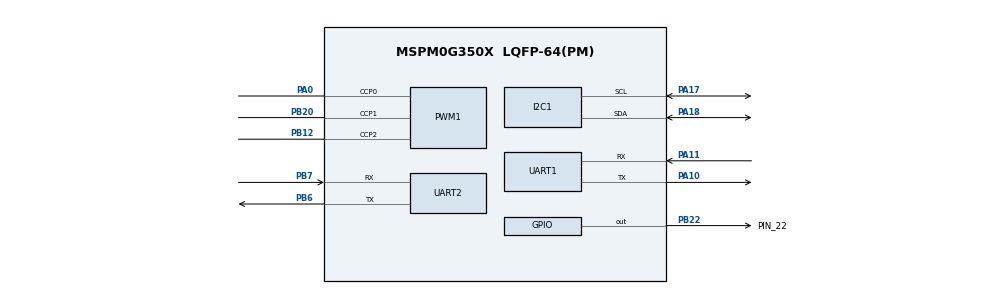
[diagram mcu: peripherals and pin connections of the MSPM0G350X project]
/**
 * @cliArgs --device "MSPM0G350X" --part "Default" --package "LQFP-64(PM)" --product "mspm0_sdk@2.10.00.04"
 * @versions {"tool":"1.26.2+4477"}
 */

/**
 * Import the modules used in this configuration.
 */
const GPIO    = scripting.addModule("/ti/driverlib/GPIO", {}, false);
const GPIO1   = GPIO.addInstance();
const GPIO2   = GPIO.addInstance();
const I2C     = scripting.addModule("/ti/driverlib/I2C", {}, false);
const I2C1    = I2C.addInstance();
const PWM     = scripting.addModule("/ti/driverlib/PWM", {}, false);
const PWM1    = PWM.addInstance();
const PWM2    = PWM.addInstance();
const SYSCTL  = scripting.addModule("/ti/driverlib/SYSCTL");
const SYSTICK = scripting.addModule("/ti/driverlib/SYSTICK");
const UART    = scripting.addModule("/ti/driverlib/UART", {}, false);
const UART1   = UART.addInstance();
const UART2   = UART.addInstance();

/**
 * Write custom configuration values to the imported modules.
 */
const divider9       = system.clockTree["UDIV"];
divider9.divideValue = 2;

const multiplier2         = system.clockTree["PLL_QDIV"];
multiplier2.multiplyValue = 4;

const mux4       = system.clockTree["EXHFMUX"];
mux4.inputSelect = "EXHFMUX_XTAL";

const mux8       = system.clockTree["HSCLKMUX"];
mux8.inputSelect = "HSCLKMUX_SYSPLL0";

const mux12       = system.clockTree["SYSPLLMUX"];
mux12.inputSelect = "zSYSPLLMUX_HFCLK";

const pinFunction4     = system.clockTree["HFXT"];
pinFunction4.enable    = true;
pinFunction4.inputFreq = 40;

GPIO1.$name                         = "use_led";
GPIO1.port                          = "PORTB";
GPIO1.associatedPins[0].$name       = "PIN_22";
GPIO1.associatedPins[0].pin.$assign = "PB22";

const Board = scripting.addModule("/ti/driverlib/Board", {}, false);

GPIO2.$name                          = "MG310";
GPIO2.associatedPins.create(4);
GPIO2.associatedPins[0].assignedPort = "PORTA";
GPIO2.associatedPins[0].$name        = "AIN1";
GPIO2.associatedPins[1].assignedPort = "PORTA";
GPIO2.associatedPins[1].$name        = "AIN2";
GPIO2.associatedPins[2].assignedPort = "PORTB";
GPIO2.associatedPins[2].$name        = "BIN1";
GPIO2.associatedPins[3].assignedPort = "PORTB";
GPIO2.associatedPins[3].$name        = "BIN2";

I2C1.$name                             = "as5600";
I2C1.basicEnableController             = true;
I2C1.basicControllerStandardBusSpeed   = "Fast";
I2C1.peripheral.$assign                = "I2C1";
I2C1.peripheral.sdaPin.$assign         = "PA18";
I2C1.peripheral.sclPin.$assign         = "PA17";
I2C1.sdaPinConfig.hideOutputInversion  = scripting.forceWrite(false);
I2C1.sdaPinConfig.onlyInternalResistor = scripting.forceWrite(false);
I2C1.sdaPinConfig.passedPeripheralType = scripting.forceWrite("Digital");
I2C1.sdaPinConfig.$name                = "ti_driverlib_gpio_GPIOPinGeneric5";
I2C1.sclPinConfig.hideOutputInversion  = scripting.forceWrite(false);
I2C1.sclPinConfig.onlyInternalResistor = scripting.forceWrite(false);
I2C1.sclPinConfig.passedPeripheralType = scripting.forceWrite("Digital");
I2C1.sclPinConfig.$name                = "ti_driverlib_gpio_GPIOPinGeneric6";

PWM1.$name                              = "BLDC";
PWM1.ccIndex                            = [0,1,2];
PWM1.timerCount                         = 1066;
PWM1.PWM_CHANNEL_0.$name                = "ti_driverlib_pwm_PWMTimerCC0";
PWM1.PWM_CHANNEL_1.$name                = "ti_driverlib_pwm_PWMTimerCC1";
PWM1.ccp0PinConfig.direction            = scripting.forceWrite("OUTPUT");
PWM1.ccp0PinConfig.hideOutputInversion  = scripting.forceWrite(false);
PWM1.ccp0PinConfig.onlyInternalResistor = scripting.forceWrite(false);
PWM1.ccp0PinConfig.passedPeripheralType = scripting.forceWrite("Digital");
PWM1.ccp0PinConfig.$name                = "ti_driverlib_gpio_GPIOPinGeneric0";
PWM1.ccp1PinConfig.direction            = scripting.forceWrite("OUTPUT");
PWM1.ccp1PinConfig.hideOutputInversion  = scripting.forceWrite(false);
PWM1.ccp1PinConfig.onlyInternalResistor = scripting.forceWrite(false);
PWM1.ccp1PinConfig.passedPeripheralType = scripting.forceWrite("Digital");
PWM1.ccp1PinConfig.$name                = "ti_driverlib_gpio_GPIOPinGeneric1";
PWM1.peripheral.$assign                 = "TIMA0";
PWM1.peripheral.ccp0Pin.$assign         = "PA0";
PWM1.peripheral.ccp1Pin.$assign         = "PB20";
PWM1.peripheral.ccp2Pin.$assign         = "PB12";
PWM1.PWM_CHANNEL_2.$name                = "ti_driverlib_pwm_PWMTimerCC2";
PWM1.ccp2PinConfig.$name                = "ti_driverlib_gpio_GPIOPinGeneric4";

PWM2.$name                              = "MG310_PWM";
PWM2.timerCount                         = 3200;
PWM2.pwmMode                            = "EDGE_ALIGN_UP";
PWM2.peripheral.$assign                 = "TIMA1";
PWM2.PWM_CHANNEL_0.$name                = "ti_driverlib_pwm_PWMTimerCC3";
PWM2.PWM_CHANNEL_1.$name                = "ti_driverlib_pwm_PWMTimerCC4";
PWM2.ccp0PinConfig.direction            = scripting.forceWrite("OUTPUT");
PWM2.ccp0PinConfig.hideOutputInversion  = scripting.forceWrite(false);
PWM2.ccp0PinConfig.onlyInternalResistor = scripting.forceWrite(false);
PWM2.ccp0PinConfig.passedPeripheralType = scripting.forceWrite("Digital");
PWM2.ccp0PinConfig.$name                = "ti_driverlib_gpio_GPIOPinGeneric7";
PWM2.ccp1PinConfig.direction            = scripting.forceWrite("OUTPUT");
PWM2.ccp1PinConfig.hideOutputInversion  = scripting.forceWrite(false);
PWM2.ccp1PinConfig.onlyInternalResistor = scripting.forceWrite(false);
PWM2.ccp1PinConfig.passedPeripheralType = scripting.forceWrite("Digital");
PWM2.ccp1PinConfig.$name                = "ti_driverlib_gpio_GPIOPinGeneric8";

SYSCTL.forceDefaultClkConfig = true;

SYSTICK.periodEnable      = true;
SYSTICK.interruptPriority = "1";
SYSTICK.period            = 32000;

UART1.targetBaudRate                   = 115200;
UART1.$name                            = "debug";
UART1.enabledInterrupts                = ["RX"];
UART1.interruptPriority                = "2";
UART1.peripheral.$assign               = "UART0";
UART1.peripheral.rxPin.$assign         = "PA11";
UART1.peripheral.txPin.$assign         = "PA10";
UART1.txPinConfig.direction            = scripting.forceWrite("OUTPUT");
UART1.txPinConfig.hideOutputInversion  = scripting.forceWrite(false);
UART1.txPinConfig.onlyInternalResistor = scripting.forceWrite(false);
UART1.txPinConfig.passedPeripheralType = scripting.forceWrite("Digital");
UART1.txPinConfig.$name                = "ti_driverlib_gpio_GPIOPinGeneric2";
UART1.rxPinConfig.hideOutputInversion  = scripting.forceWrite(false);
UART1.rxPinConfig.onlyInternalResistor = scripting.forceWrite(false);
UART1.rxPinConfig.passedPeripheralType = scripting.forceWrite("Digital");
UART1.rxPinConfig.$name                = "ti_driverlib_gpio_GPIOPinGeneric3";

UART2.$name                            = "fishpath";
UART2.targetBaudRate                   = 115200;
UART2.peripheral.rxPin.$assign         = "PB7";
UART2.peripheral.txPin.$assign         = "PB6";
UART2.txPinConfig.direction            = scripting.forceWrite("OUTPUT");
UART2.txPinConfig.hideOutputInversion  = scripting.forceWrite(false);
UART2.txPinConfig.onlyInternalResistor = scripting.forceWrite(false);
UART2.txPinConfig.passedPeripheralType = scripting.forceWrite("Digital");
UART2.txPinConfig.$name                = "ti_driverlib_gpio_GPIOPinGeneric9";
UART2.rxPinConfig.hideOutputInversion  = scripting.forceWrite(false);
UART2.rxPinConfig.onlyInternalResistor = scripting.forceWrite(false);
UART2.rxPinConfig.passedPeripheralType = scripting.forceWrite("Digital");
UART2.rxPinConfig.$name                = "ti_driverlib_gpio_GPIOPinGeneric10";

/**
 * Pinmux solution for unlocked pins/peripherals. This ensures that minor changes to the automatic solver in a future
 * version of the tool will not impact the pinmux you originally saw.  These lines can be completely deleted in order to
 * re-solve from scratch.
 */
pinFunction4.peripheral.$suggestSolution           = "SYSCTL";
pinFunction4.peripheral.hfxInPin.$suggestSolution  = "PA5";
pinFunction4.peripheral.hfxOutPin.$suggestSolution = "PA6";
Board.peripheral.$suggestSolution                  = "DEBUGSS";
Board.peripheral.swclkPin.$suggestSolution         = "PA20";
Board.peripheral.swdioPin.$suggestSolution         = "PA19";
GPIO2.associatedPins[0].pin.$suggestSolution       = "PA13";
GPIO2.associatedPins[1].pin.$suggestSolution       = "PA12";
GPIO2.associatedPins[2].pin.$suggestSolution       = "PB14";
GPIO2.associatedPins[3].pin.$suggestSolution       = "PB13";
PWM2.peripheral.ccp0Pin.$suggestSolution           = "PA15";
PWM2.peripheral.ccp1Pin.$suggestSolution           = "PA16";
SYSCTL.peripheral.$suggestSolution                 = "SYSCTL";
UART2.peripheral.$suggestSolution                  = "UART1";
